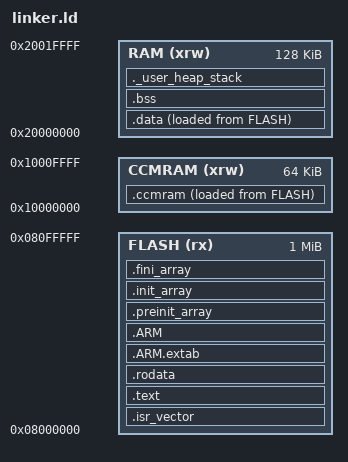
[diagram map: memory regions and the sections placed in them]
/**
 * @file    linker.ld
 * @brief   STM32F407VG 链接脚本
 * 
 * Klipper MCU 移植项目
 * 
 * 内存布局:
 *   - Flash: 1MB @ 0x08000000
 *   - Main RAM: 128KB @ 0x20000000
 *   - CCM RAM: 64KB @ 0x10000000 (仅 CPU 可访问，无 DMA)
 */

/* =============================================================================
 * 入口点
 * ============================================================================= */
ENTRY(Reset_Handler)

/* =============================================================================
 * 栈和堆配置
 * ============================================================================= */

/* 主栈大小 (用于 main 和中断) */
_Min_Stack_Size = 0x1000;   /* 4KB */

/* 堆大小 (嵌入式通常不使用动态内存) */
_Min_Heap_Size = 0x400;     /* 1KB */

/* =============================================================================
 * 内存区域定义
 * ============================================================================= */
MEMORY
{
    /* Flash 存储器 - 1MB */
    FLASH (rx)      : ORIGIN = 0x08000000, LENGTH = 1024K
    
    /* 主 SRAM - 128KB (可被 DMA 访问) */
    RAM (xrw)       : ORIGIN = 0x20000000, LENGTH = 128K
    
    /* CCM SRAM - 64KB (仅 CPU 可访问，适合栈和关键数据) */
    CCMRAM (xrw)    : ORIGIN = 0x10000000, LENGTH = 64K
}

/* =============================================================================
 * 段定义
 * ============================================================================= */
SECTIONS
{
    /* -------------------------------------------------------------------------
     * 中断向量表 (必须在 Flash 起始位置)
     * ------------------------------------------------------------------------- */
    .isr_vector :
    {
        . = ALIGN(4);
        KEEP(*(.isr_vector))    /* 中断向量表 */
        . = ALIGN(4);
    } >FLASH

    /* -------------------------------------------------------------------------
     * 代码段
     * ------------------------------------------------------------------------- */
    .text :
    {
        . = ALIGN(4);
        *(.text)                /* 代码 */
        *(.text*)               /* 代码 (gcc 生成的子段) */
        *(.glue_7)              /* ARM/Thumb 互操作代码 */
        *(.glue_7t)
        *(.eh_frame)

        KEEP(*(.init))          /* 初始化代码 */
        KEEP(*(.fini))          /* 终止代码 */

        . = ALIGN(4);
        _etext = .;             /* 代码段结束地址 */
    } >FLASH

    /* -------------------------------------------------------------------------
     * 只读数据段
     * ------------------------------------------------------------------------- */
    .rodata :
    {
        . = ALIGN(4);
        *(.rodata)              /* 只读数据 */
        *(.rodata*)             /* 只读数据 (gcc 生成的子段) */
        . = ALIGN(4);
    } >FLASH

    /* -------------------------------------------------------------------------
     * ARM 异常处理表
     * ------------------------------------------------------------------------- */
    .ARM.extab :
    {
        *(.ARM.extab* .gnu.linkonce.armextab.*)
    } >FLASH

    .ARM :
    {
        __exidx_start = .;
        *(.ARM.exidx*)
        __exidx_end = .;
    } >FLASH

    /* -------------------------------------------------------------------------
     * 预初始化数组 (C++ 构造函数等)
     * ------------------------------------------------------------------------- */
    .preinit_array :
    {
        PROVIDE_HIDDEN(__preinit_array_start = .);
        KEEP(*(.preinit_array*))
        PROVIDE_HIDDEN(__preinit_array_end = .);
    } >FLASH

    .init_array :
    {
        PROVIDE_HIDDEN(__init_array_start = .);
        KEEP(*(SORT(.init_array.*)))
        KEEP(*(.init_array*))
        PROVIDE_HIDDEN(__init_array_end = .);
    } >FLASH

    .fini_array :
    {
        PROVIDE_HIDDEN(__fini_array_start = .);
        KEEP(*(SORT(.fini_array.*)))
        KEEP(*(.fini_array*))
        PROVIDE_HIDDEN(__fini_array_end = .);
    } >FLASH

    /* -------------------------------------------------------------------------
     * 已初始化数据段 (从 Flash 复制到 RAM)
     * ------------------------------------------------------------------------- */
    _sidata = LOADADDR(.data);  /* Flash 中 .data 段的起始地址 */

    .data :
    {
        . = ALIGN(4);
        _sdata = .;             /* RAM 中 .data 段的起始地址 */
        *(.data)                /* 已初始化数据 */
        *(.data*)               /* 已初始化数据 (gcc 生成的子段) */
        *(.RamFunc)             /* 需要在 RAM 中执行的函数 */
        *(.RamFunc*)

        . = ALIGN(4);
        _edata = .;             /* RAM 中 .data 段的结束地址 */
    } >RAM AT> FLASH

    /* -------------------------------------------------------------------------
     * CCM RAM 数据段 (用于关键数据，无 DMA 访问)
     * ------------------------------------------------------------------------- */
    _siccmram = LOADADDR(.ccmram);

    .ccmram :
    {
        . = ALIGN(4);
        _sccmram = .;           /* CCM RAM 起始地址 */
        *(.ccmram)              /* CCM RAM 数据 */
        *(.ccmram*)

        . = ALIGN(4);
        _eccmram = .;           /* CCM RAM 结束地址 */
    } >CCMRAM AT> FLASH

    /* -------------------------------------------------------------------------
     * 未初始化数据段 (BSS)
     * ------------------------------------------------------------------------- */
    .bss :
    {
        . = ALIGN(4);
        _sbss = .;              /* BSS 段起始地址 */
        __bss_start__ = _sbss;
        *(.bss)                 /* 未初始化数据 */
        *(.bss*)                /* 未初始化数据 (gcc 生成的子段) */
        *(COMMON)               /* 公共符号 */

        . = ALIGN(4);
        _ebss = .;              /* BSS 段结束地址 */
        __bss_end__ = _ebss;
    } >RAM

    /* -------------------------------------------------------------------------
     * 用户堆段
     * ------------------------------------------------------------------------- */
    ._user_heap_stack :
    {
        . = ALIGN(8);
        PROVIDE(end = .);
        PROVIDE(_end = .);
        . = . + _Min_Heap_Size;
        . = . + _Min_Stack_Size;
        . = ALIGN(8);
    } >RAM

    /* -------------------------------------------------------------------------
     * 栈顶指针 (RAM 末尾)
     * ------------------------------------------------------------------------- */
    _estack = ORIGIN(RAM) + LENGTH(RAM);

    /* -------------------------------------------------------------------------
     * 移除调试信息中的库代码
     * ------------------------------------------------------------------------- */
    /DISCARD/ :
    {
        libc.a(*)
        libm.a(*)
        libgcc.a(*)
    }

    /* -------------------------------------------------------------------------
     * ARM 属性段
     * ------------------------------------------------------------------------- */
    .ARM.attributes 0 :
    {
        *(.ARM.attributes)
    }
}

/* =============================================================================
 * 导出符号 (供启动代码使用)
 * ============================================================================= */

/* Flash 中数据段的加载地址 */
PROVIDE(_sidata = LOADADDR(.data));

/* RAM 中数据段的起始和结束地址 */
PROVIDE(_sdata = ADDR(.data));
PROVIDE(_edata = ADDR(.data) + SIZEOF(.data));

/* BSS 段的起始和结束地址 */
PROVIDE(_sbss = ADDR(.bss));
PROVIDE(_ebss = ADDR(.bss) + SIZEOF(.bss));

/* 栈顶地址 */
PROVIDE(_estack = ORIGIN(RAM) + LENGTH(RAM));

/* 堆起始地址 */
PROVIDE(_heap_start = _ebss);
PROVIDE(_heap_end = _estack - _Min_Stack_Size);

